# STM32L433xx register map
File version: 1.0
Registers are 32-bit, read-write, reset 0x0 unless marked. A register's access mark holds for its fields unless they carry their own. Offsets are from the block's base; [hi:lo] are bit positions; {n}, {i} and the like mark numbered series.

## COMP12_COMMON
Base 0x40010204
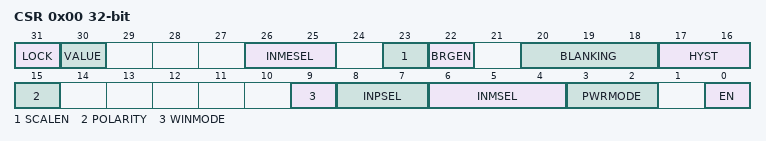
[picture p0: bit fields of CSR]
0x00 CSR — COMP control and status register, used for bits common to several COMP instances
  [31] LOCK — Comparator lock
  [30] VALUE — Comparator output level
  [26:25] INMESEL — Comparator input minus extended selection
  [23] SCALEN — Comparator scaler bridge enable
  [22] BRGEN — Comparator voltage scaler enable
  [20:18] BLANKING — Comparator blanking source
    0=NONE (Comparator output without blanking); 1=TIM1_OC5_COMP1 (Comparator output blanking source TIM1 OC5 (specific to COMP instance: COMP1)); 2=TIM2_OC3_COMP1 (Comparator output blanking source TIM2 OC3 (specific to COMP instance: COMP1)); 4=TIM3_OC3_COMP1 (Comparator output blanking source TIM3 OC3 (specific to COMP instance: COMP1))
  [17:16] HYST — Comparator hysteresis
    0=NONE (No hysteresis); 1=LOW (Hysteresis level low); 2=MEDIUM (Hysteresis level medium); 3=HIGH (Hysteresis level high)
  [15] POLARITY — Comparator output polarity
    0=NONINVERTED (COMP output polarity is not inverted: comparator output is high when the plus (non-inverting) input is at a higher voltage than the minus (inverting) input); 1=INVERTED (COMP output polarity is inverted: comparator output is low when the plus (non-inverting) input is at a lower voltage than the minus (inverting) input)
  [9] WINMODE — Pair of comparators window mode. Bit intended to be used with COMP common instance (COMP_Common_TypeDef)
    0=DISABLE (Window mode disable: Comparators 1 and 2 are independent); 1=COMP1_INPUT_PLUS_COMMON (Window mode enable: Comparators instances pair COMP1 and COMP2 have their input plus connected together. The common input is COMP1 input plus (COMP2 input plus is no more accessible).)
  [8:7] INPSEL — Comparator input plus selection
    0=IO1 (Comparator input plus connected to IO1 (pin PC5 for COMP1, pin PB4 for COMP2)); 1=IO2 (Comparator input plus connected to IO2 (pin PB2 for COMP1, pin PB6 for COMP2)); 2=IO3 (Comparator input plus connected to IO3 (pin PA1 for COMP1, pin PA3 for COMP2))
  [6:4] INMSEL — Comparator input minus selection
  [3:2] PWRMODE — Comparator power mode
    0=HIGHSPEED (COMP power mode to high speed); 1=MEDIUMSPEED (COMP power mode to medium speed); 3=ULTRALOWPOWER (COMP power mode to ultra-low power)
  [0] EN — Comparator enable

## EXTI — External Interrupt/Event Controller
Base 0x40010400
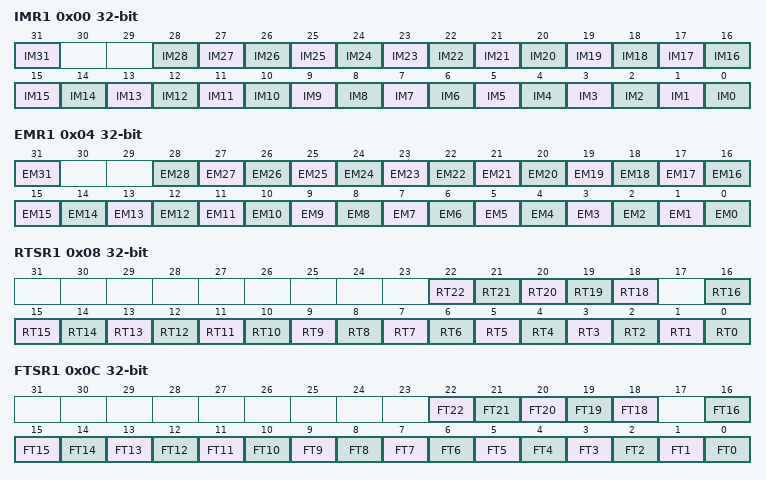
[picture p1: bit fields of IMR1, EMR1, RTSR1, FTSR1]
0x00 IMR1 — EXTI Interrupt mask register 1
  [31] IM31 — Interrupt Mask on line 31
  [n] IM{n} (n=0..28) — Interrupt Mask on line {n}
0x04 EMR1 — EXTI Event mask register 1
  [31] EM31 — Event Mask on line 31
  [n] EM{n} (n=0..28) — Event Mask on line {n}
0x08 RTSR1 — EXTI Rising trigger selection register 1
  [n] RT{n} (n=18..22) — Rising trigger event configuration bit of line {n}
  [n] RT{n} (n=0..16) — Rising trigger event configuration bit of line {n}
0x0C FTSR1 — EXTI Falling trigger selection register 1
  [n] FT{n} (n=18..22) — Falling trigger event configuration bit of line {n}
  [n] FT{n} (n=0..16) — Falling trigger event configuration bit of line {n}
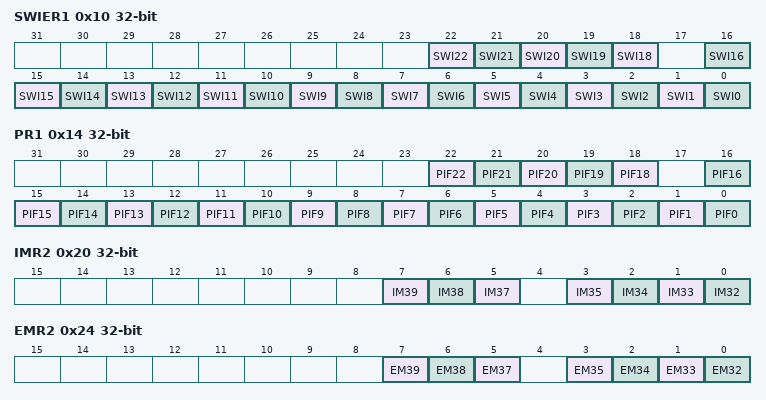
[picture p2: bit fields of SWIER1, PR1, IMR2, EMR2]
0x10 SWIER1 — EXTI Software interrupt event register 1
  [n] SWI{n} (n=18..22) — Software Interrupt on line {n}
  [n] SWI{n} (n=0..16) — Software Interrupt on line {n}
0x14 PR1 — EXTI Pending register 1
  [n] PIF{n} (n=18..22) — Pending bit for line {n}
  [n] PIF{n} (n=0..16) — Pending bit for line {n}
0x20 IMR2 — EXTI Interrupt mask register 2
  [7] IM39 — Interrupt Mask on line 39
  [6] IM38 — Interrupt Mask on line 38
  [5] IM37 — Interrupt Mask on line 37
  [n-32] IM{n} (n=32..35) — Interrupt Mask on line {n}
0x24 EMR2 — EXTI Event mask register 2
  [7] EM39 — Event Mask on line 39
  [6] EM38 — Event Mask on line 38
  [5] EM37 — Event Mask on line 37
  [n-32] EM{n} (n=32..35) — Event Mask on line {n}
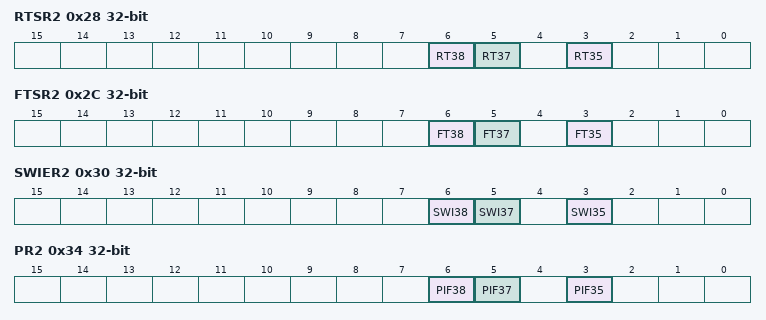
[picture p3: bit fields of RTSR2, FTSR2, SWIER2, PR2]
0x28 RTSR2 — EXTI Rising trigger selection register 2
  [6] RT38 — Rising trigger event configuration bit of line 38
  [5] RT37 — Rising trigger event configuration bit of line 37
  [3] RT35 — Rising trigger event configuration bit of line 35
0x2C FTSR2 — EXTI Falling trigger selection register 2
  [6] FT38 — Falling trigger event configuration bit of line 38
  [5] FT37 — Falling trigger event configuration bit of line 37
  [3] FT35 — Falling trigger event configuration bit of line 35
0x30 SWIER2 — EXTI Software interrupt event register 2
  [6] SWI38 — Software Interrupt on line 38
  [5] SWI37 — Software Interrupt on line 37
  [3] SWI35 — Software Interrupt on line 35
0x34 PR2 — EXTI Pending register 2
  [6] PIF38 — Pending bit for line 38
  [5] PIF37 — Pending bit for line 37
  [3] PIF35 — Pending bit for line 35
